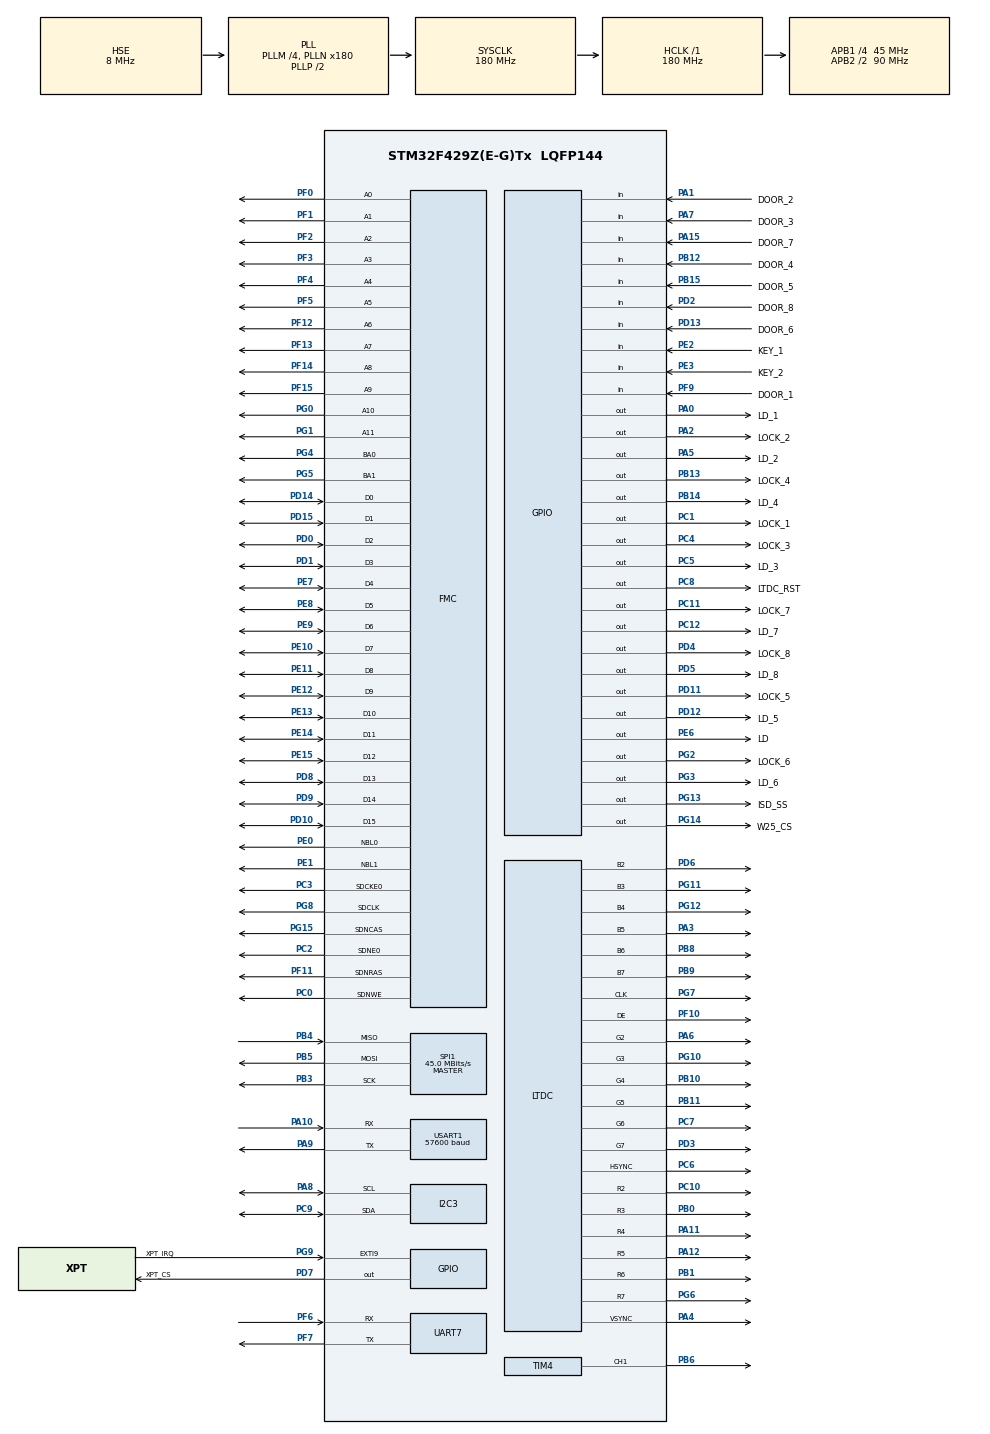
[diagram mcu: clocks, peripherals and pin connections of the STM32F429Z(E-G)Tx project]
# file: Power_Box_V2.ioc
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Dma.Request0=UART7_RX
Dma.UART7_RX.0.Direction=DMA_PERIPH_TO_MEMORY
Dma.UART7_RX.0.FIFOMode=DMA_FIFOMODE_DISABLE
Dma.UART7_RX.0.Instance=DMA1_Stream3
Dma.UART7_RX.0.MemDataAlignment=DMA_MDATAALIGN_BYTE
Dma.UART7_RX.0.MemInc=DMA_MINC_ENABLE
Dma.UART7_RX.0.Mode=DMA_CIRCULAR
Dma.UART7_RX.0.PeriphDataAlignment=DMA_PDATAALIGN_BYTE
Dma.UART7_RX.0.PeriphInc=DMA_PINC_DISABLE
Dma.UART7_RX.0.Priority=DMA_PRIORITY_LOW
FMC.SDBank1=FMC_SDRAM_BANK1
Mcu.Family=STM32F4
Mcu.Name=STM32F429Z(E-G)Tx
Mcu.Package=LQFP144
NVIC.DMA1_Stream3_IRQn=true\:0\:0\:false\:false\:true\:false\:true\:true
NVIC.PriorityGroup=NVIC_PRIORITYGROUP_4
NVIC.TIM8_TRG_COM_TIM14_IRQn=true\:0\:0\:false\:false\:true\:true\:true\:true
NVIC.UART7_IRQn=true\:0\:0\:false\:false\:true\:true\:true\:true
PA0/WKUP.GPIO_Label=LD_1
PA0/WKUP.Signal=GPIO_Output
PA1.GPIO_Label=DOOR_2
PA1.Signal=GPIO_Input
PA10.Mode=Asynchronous
PA10.Signal=USART1_RX
PA11.Mode=RGB666
PA11.Signal=LTDC_R4
PA12.Mode=RGB666
PA12.Signal=LTDC_R5
PA13.Mode=Serial_Wire
PA13.Signal=SYS_JTMS-SWDIO
PA14.Mode=Serial_Wire
PA14.Signal=SYS_JTCK-SWCLK
PA15.GPIO_Label=DOOR_7
PA15.Signal=GPIO_Input
PA2.GPIO_Label=LOCK_2
PA2.Signal=GPIO_Output
PA3.Mode=RGB666
PA3.Signal=LTDC_B5
PA4.Mode=RGB666
PA4.Signal=LTDC_VSYNC
PA5.GPIO_Label=LD_2
PA5.Signal=GPIO_Output
PA6.Mode=RGB666
PA6.Signal=LTDC_G2
PA7.GPIO_Label=DOOR_3
PA7.Signal=GPIO_Input
PA8.Mode=I2C
PA8.Signal=I2C3_SCL
PA9.Mode=Asynchronous
PA9.Signal=USART1_TX
PB0.Mode=RGB666
PB0.Signal=LTDC_R3
PB1.Mode=RGB666
PB1.Signal=LTDC_R6
PB10.Mode=RGB666
PB10.Signal=LTDC_G4
PB11.Mode=RGB666
PB11.Signal=LTDC_G5
PB12.GPIO_Label=DOOR_4
PB12.Signal=GPIO_Input
PB13.GPIO_Label=LOCK_4
PB13.Signal=GPIO_Output
PB14.GPIO_Label=LD_4
PB14.Signal=GPIO_Output
PB15.GPIO_Label=DOOR_5
PB15.Signal=GPIO_Input
PB3.Mode=Full_Duplex_Master
PB3.Signal=SPI1_SCK
PB4.Mode=Full_Duplex_Master
PB4.Signal=SPI1_MISO
PB5.Mode=Full_Duplex_Master
PB5.Signal=SPI1_MOSI
PB6.Signal=S_TIM4_CH1
PB8.Mode=RGB666
PB8.Signal=LTDC_B6
PB9.Mode=RGB666
PB9.Signal=LTDC_B7
PC0.Signal=FMC_SDNWE
PC1.GPIO_Label=LOCK_1
PC1.Signal=GPIO_Output
PC10.Mode=RGB666
PC10.Signal=LTDC_R2
PC11.GPIO_Label=LOCK_7
PC11.Signal=GPIO_Output
PC12.GPIO_Label=LD_7
PC12.Signal=GPIO_Output
PC14/OSC32_IN.Mode=LSE-External-Oscillator
PC14/OSC32_IN.Signal=RCC_OSC32_IN
PC15/OSC32_OUT.Mode=LSE-External-Oscillator
PC15/OSC32_OUT.Signal=RCC_OSC32_OUT
PC2.Mode=SdramChipSelect1_1
PC2.Signal=FMC_SDNE0
PC3.Mode=SdramChipSelect1_1
PC3.Signal=FMC_SDCKE0
PC4.GPIO_Label=LOCK_3
PC4.Signal=GPIO_Output
PC5.GPIO_Label=LD_3
PC5.Signal=GPIO_Output
PC6.Mode=RGB666
PC6.Signal=LTDC_HSYNC
PC7.Mode=RGB666
PC7.Signal=LTDC_G6
PC8.GPIO_Label=LTDC_RST
PC8.Signal=GPIO_Output
PC9.Mode=I2C
PC9.Signal=I2C3_SDA
PD0.Signal=FMC_D2_DA2
PD1.Signal=FMC_D3_DA3
PD10.Signal=FMC_D15_DA15
PD11.GPIO_Label=LOCK_5
PD11.Signal=GPIO_Output
PD12.GPIO_Label=LD_5
PD12.Signal=GPIO_Output
PD13.GPIO_Label=DOOR_6
PD13.Signal=GPIO_Input
PD14.Signal=FMC_D0_DA0
PD15.Signal=FMC_D1_DA1
PD2.GPIO_Label=DOOR_8
PD2.Signal=GPIO_Input
PD3.Mode=RGB666
PD3.Signal=LTDC_G7
PD4.GPIO_Label=LOCK_8
PD4.Signal=GPIO_Output
PD5.GPIO_Label=LD_8
PD5.Signal=GPIO_Output
PD6.Mode=RGB666
PD6.Signal=LTDC_B2
PD7.GPIO_Label=XPT_CS
PD7.Signal=GPIO_Output
PD8.Signal=FMC_D13_DA13
PD9.Signal=FMC_D14_DA14
PE0.Signal=FMC_NBL0
PE1.Signal=FMC_NBL1
PE10.Signal=FMC_D7_DA7
PE11.Signal=FMC_D8_DA8
PE12.Signal=FMC_D9_DA9
PE13.Signal=FMC_D10_DA10
PE14.Signal=FMC_D11_DA11
PE15.Signal=FMC_D12_DA12
PE2.GPIO_Label=KEY_1
PE2.Signal=GPIO_Input
PE3.GPIO_Label=KEY_2
PE3.Signal=GPIO_Input
PE6.GPIO_Label=LD
PE6.Signal=GPIO_Output
PE7.Signal=FMC_D4_DA4
PE8.Signal=FMC_D5_DA5
PE9.Signal=FMC_D6_DA6
PF0.Signal=FMC_A0
PF1.Signal=FMC_A1
PF10.Mode=RGB666
PF10.Signal=LTDC_DE
PF11.Signal=FMC_SDNRAS
PF12.Signal=FMC_A6
PF13.Signal=FMC_A7
PF14.Signal=FMC_A8
PF15.Signal=FMC_A9
PF2.Signal=FMC_A2
PF3.Signal=FMC_A3
PF4.Signal=FMC_A4
PF5.Signal=FMC_A5
PF6.Mode=Asynchronous
PF6.Signal=UART7_RX
PF7.Mode=Asynchronous
PF7.Signal=UART7_TX
PF9.GPIO_Label=DOOR_1
PF9.Signal=GPIO_Input
PG0.Signal=FMC_A10
PG1.Signal=FMC_A11
PG10.Mode=RGB666
PG10.Signal=LTDC_G3
PG11.Mode=RGB666
PG11.Signal=LTDC_B3
PG12.Mode=RGB666
PG12.Signal=LTDC_B4
PG13.GPIO_Label=ISD_SS
PG13.Signal=GPIO_Output
PG14.GPIO_Label=W25_CS
PG14.Signal=GPIO_Output
PG15.Signal=FMC_SDNCAS
PG2.GPIO_Label=LOCK_6
PG2.Signal=GPIO_Output
PG3.GPIO_Label=LD_6
PG3.Signal=GPIO_Output
PG4.Signal=FMC_A14_BA0
PG5.Signal=FMC_A15_BA1
PG6.Mode=RGB666
PG6.Signal=LTDC_R7
PG7.Mode=RGB666
PG7.Signal=LTDC_CLK
PG8.Signal=FMC_SDCLK
PG9.GPIO_Label=XPT_IRQ
PG9.Signal=GPXTI9
PH0/OSC_IN.Mode=HSE-External-Oscillator
PH0/OSC_IN.Signal=RCC_OSC_IN
PH1/OSC_OUT.Mode=HSE-External-Oscillator
PH1/OSC_OUT.Signal=RCC_OSC_OUT
ProjectManager.HeapSize=0x2000
ProjectManager.StackSize=0x2000
ProjectManager.TargetToolchain=MDK-ARM V5
RCC.48MHZClocksFreq_Value=90000000
RCC.AHBFreq_Value=180000000
RCC.APB1CLKDivider=RCC_HCLK_DIV4
RCC.APB1Freq_Value=45000000
RCC.APB1TimFreq_Value=90000000
RCC.APB2CLKDivider=RCC_HCLK_DIV2
RCC.APB2Freq_Value=90000000
RCC.APB2TimFreq_Value=180000000
RCC.CortexFreq_Value=180000000
RCC.EnbaleCSS=true
RCC.HCLKFreq_Value=180000000
RCC.HSE_VALUE=8000000
RCC.HSI_VALUE=16000000
RCC.PLLM=4
RCC.PLLN=180
RCC.PLLSAIN=50
RCC.PLLSourceVirtual=RCC_PLLSOURCE_HSE
RCC.RCC_RTC_Clock_Source=RCC_RTCCLKSOURCE_LSE
RCC.RCC_RTC_Clock_SourceVirtual=RCC_RTCCLKSOURCE_LSE
RCC.SYSCLKFreq_VALUE=180000000
RCC.SYSCLKSource=RCC_SYSCLKSOURCE_PLLCLK
RCC.VCOOutputFreq_Value=360000000
SH.FMC_A0.0=FMC_A0,12b-sda1
SH.FMC_A1.0=FMC_A1,12b-sda1
SH.FMC_A10.0=FMC_A10,12b-sda1
SH.FMC_A11.0=FMC_A11,12b-sda1
SH.FMC_A14_BA0.0=FMC_BA0,FourSdramBanks1
SH.FMC_A15_BA1.0=FMC_BA1,FourSdramBanks1
SH.FMC_A2.0=FMC_A2,12b-sda1
SH.FMC_A3.0=FMC_A3,12b-sda1
SH.FMC_A4.0=FMC_A4,12b-sda1
SH.FMC_A5.0=FMC_A5,12b-sda1
SH.FMC_A6.0=FMC_A6,12b-sda1
SH.FMC_A7.0=FMC_A7,12b-sda1
SH.FMC_A8.0=FMC_A8,12b-sda1
SH.FMC_A9.0=FMC_A9,12b-sda1
SH.FMC_D0_DA0.0=FMC_D0,sd-16b-d1
SH.FMC_D10_DA10.0=FMC_D10,sd-16b-d1
SH.FMC_D11_DA11.0=FMC_D11,sd-16b-d1
SH.FMC_D12_DA12.0=FMC_D12,sd-16b-d1
SH.FMC_D13_DA13.0=FMC_D13,sd-16b-d1
SH.FMC_D14_DA14.0=FMC_D14,sd-16b-d1
SH.FMC_D15_DA15.0=FMC_D15,sd-16b-d1
SH.FMC_D1_DA1.0=FMC_D1,sd-16b-d1
SH.FMC_D2_DA2.0=FMC_D2,sd-16b-d1
SH.FMC_D3_DA3.0=FMC_D3,sd-16b-d1
SH.FMC_D4_DA4.0=FMC_D4,sd-16b-d1
SH.FMC_D5_DA5.0=FMC_D5,sd-16b-d1
SH.FMC_D6_DA6.0=FMC_D6,sd-16b-d1
SH.FMC_D7_DA7.0=FMC_D7,sd-16b-d1
SH.FMC_D8_DA8.0=FMC_D8,sd-16b-d1
SH.FMC_D9_DA9.0=FMC_D9,sd-16b-d1
SH.FMC_NBL0.0=FMC_NBL0,Sd2ByteEnable1
SH.FMC_NBL1.0=FMC_NBL1,Sd2ByteEnable1
SH.FMC_SDCLK.0=FMC_SDCLK,12b-sda1
SH.FMC_SDNCAS.0=FMC_SDNCAS,12b-sda1
SH.FMC_SDNRAS.0=FMC_SDNRAS,12b-sda1
SH.FMC_SDNWE.0=FMC_SDNWE,12b-sda1
SH.S_TIM4_CH1.0=TIM4_CH1,PWM Generation1 CH1
SPI1.CalculateBaudRate=45.0 MBits/s
SPI1.Direction=SPI_DIRECTION_2LINES
SPI1.Mode=SPI_MODE_MASTER
SPI1.VirtualType=VM_MASTER
TIM14.AutoReloadPreload=TIM_AUTORELOAD_PRELOAD_ENABLE
TIM14.Period=999
TIM14.Prescaler=8999
TIM4.Channel-PWM\ Generation1\ CH1=TIM_CHANNEL_1
UART7.VirtualMode=Asynchronous
USART1.BaudRate=57600
USART1.VirtualMode=VM_ASYNC
VP_RTC_VS_RTC_Activate.Mode=RTC_Enabled
VP_RTC_VS_RTC_Calendar.Mode=RTC_Calendar
VP_TIM14_VS_ClockSourceINT.Mode=Enable_Timer
board=custom

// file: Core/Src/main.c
/* USER CODE BEGIN Header */
/**
  ******************************************************************************
  * @file           : main.c
  * @brief          : Main program body
  ******************************************************************************
  * @attention
  *
  * Copyright (c) 2026 STMicroelectronics.
  * All rights reserved.
  *
  * This software is licensed under terms that can be found in the LICENSE file
  * in the root directory of this software component.
  * If no LICENSE file comes with this software, it is provided AS-IS.
  *
  ******************************************************************************
  */
/* USER CODE END Header */
#include "main.h"

/* USER CODE BEGIN Includes */
#include "w25q32.h"
#include "spi_bus.h"
#include "lcd.h"
#include "backlight.h"
#include "sdram.h"
#include "touch.h"
#include "isd1730.h"
#include "zfm40.h"
#include "AT24Cxx.h"
#include "rtc.h"
#include "debug_link.h"
#include "ui_interface.h"
#include "channel_hw.h"
#include "channel_manager.h"
#include "storage.h"
#include "log.h"
#include "flow_manager.h"
/* USER CODE END Includes */

/* USER CODE BEGIN PD */
/* PA0 blinks once when a scanned finger matches a template already
   stored in the module; not currently driven by application code, but
   left configured (safe, off) as an available feedback hook. */
#define FP_MATCH_LED_GPIO_Port     GPIOA
#define FP_MATCH_LED_Pin           GPIO_PIN_0
/* USER CODE END PD */

I2C_HandleTypeDef hi2c3;

LTDC_HandleTypeDef hltdc;

RTC_HandleTypeDef hrtc;

SPI_HandleTypeDef hspi1;

TIM_HandleTypeDef htim4;
TIM_HandleTypeDef htim14;

UART_HandleTypeDef huart7;
UART_HandleTypeDef huart1;
DMA_HandleTypeDef hdma_uart7_rx;

SDRAM_HandleTypeDef hsdram1;

void SystemClock_Config(void);
static void MX_GPIO_Init(void);
static void MX_DMA_Init(void);
static void MX_LTDC_Init(void);
static void MX_FMC_Init(void);
static void MX_I2C3_Init(void);
static void MX_SPI1_Init(void);
static void MX_USART1_UART_Init(void);
static void MX_TIM4_Init(void);
static void MX_RTC_Init(void);
static void MX_TIM14_Init(void);
static void MX_UART7_Init(void);

int main(void)
{

  /* MCU Configuration--------------------------------------------------------*/

  /* Reset of all peripherals, Initializes the Flash interface and the Systick. */
  HAL_Init();

  /* Configure the system clock */
  SystemClock_Config();

  /* Initialize all configured peripherals */
  MX_GPIO_Init();
  MX_DMA_Init();
  MX_LTDC_Init();
  MX_FMC_Init();
  MX_I2C3_Init();
  MX_SPI1_Init();
  MX_USART1_UART_Init();
  MX_TIM4_Init();
  MX_RTC_Init();
  MX_TIM14_Init();
  MX_UART7_Init();
  /* USER CODE BEGIN 2 */

  HAL_TIM_Base_Start_IT(&htim14);

  /* DebugLink first: no peripheral dependency beyond MX_UART7_Init()
   * (already done above), and every later init-failure message below
   * needs it ready to actually reach the PC tool. */
  DebugLink_Init(&huart7);
  DebugLink_RegisterCallback(UI_ProcessIncomingLine);
  UI_Init();

  /* ---- Boot sequence: order matters, see each module's header for its
   * documented dependency on the ones before it. ---- */
  Backlight_Init();
  Backlight_SetBrightness(50);

  RTC_Init();

  SPI_Bus_Init();                 /* must precede ISD1730_Init() / W25Q32_Init() */
  if (ISD1730_Init() != ISD_OK)
  {
      DebugLink_SendLine("OUT:LOG:ISD1730_Init failed");
  }
  if (W25Q32_Init() != W25_OK)
  {
      DebugLink_SendLine("OUT:LOG:W25Q32_Init failed");
  }

  if (ZFM40_Init() != ZFM_OK)
  {
      DebugLink_SendLine("OUT:LOG:ZFM40_Init failed");
  }
  HAL_Delay(500); /* module boot time before the first command */
  {
      uint8_t confirm;
      if ((ZFM40_VerifyPassword(0x00000000, &confirm) != ZFM_OK) || (confirm != ZFM_CONF_OK))
      {
          DebugLink_SendLine("OUT:LOG:ZFM40 password verify failed");
      }
  }

  if (ChannelHW_Init() != SYS_OK)     /* before Storage_Init()/ChannelManager_Init() */
  {
      DebugLink_SendLine("OUT:LOG:ChannelHW_Init failed");
  }
  if (Storage_Init() != SYS_OK)       /* before Log_Init()/ChannelManager_Init() */
  {
      DebugLink_SendLine("OUT:LOG:Storage_Init failed");
  }
  if (Log_Init() != SYS_OK)           /* needs Storage_Init() + W25Q32_Init() */
  {
      DebugLink_SendLine("OUT:LOG:Log_Init failed");
  }
  if (ChannelManager_Init() != SYS_OK) /* needs Storage_Init() + ChannelHW_Init() */
  {
      DebugLink_SendLine("OUT:LOG:ChannelManager_Init failed");
  }

  FlowManager_Init();
  /* USER CODE END 2 */

  /* Infinite loop */
  while (1)
  {

    /* USER CODE BEGIN 3 */
    DebugLink_Process();
    UI_Tick();
    FlowManager_Process();
  }
  /* USER CODE END 3 */
}

void SystemClock_Config(void)
{
  RCC_OscInitTypeDef RCC_OscInitStruct = {0};
  RCC_ClkInitTypeDef RCC_ClkInitStruct = {0};

  /** Configure the main internal regulator output voltage
  */
  __HAL_RCC_PWR_CLK_ENABLE();
  __HAL_PWR_VOLTAGESCALING_CONFIG(PWR_REGULATOR_VOLTAGE_SCALE1);

  /** Initializes the RCC Oscillators according to the specified parameters
  * in the RCC_OscInitTypeDef structure.
  */
  RCC_OscInitStruct.OscillatorType = RCC_OSCILLATORTYPE_HSE|RCC_OSCILLATORTYPE_LSE;
  RCC_OscInitStruct.HSEState = RCC_HSE_ON;
  RCC_OscInitStruct.LSEState = RCC_LSE_ON;
  RCC_OscInitStruct.PLL.PLLState = RCC_PLL_ON;
  RCC_OscInitStruct.PLL.PLLSource = RCC_PLLSOURCE_HSE;
  RCC_OscInitStruct.PLL.PLLM = 4;
  RCC_OscInitStruct.PLL.PLLN = 180;
  RCC_OscInitStruct.PLL.PLLP = RCC_PLLP_DIV2;
  RCC_OscInitStruct.PLL.PLLQ = 4;
  if (HAL_RCC_OscConfig(&RCC_OscInitStruct) != HAL_OK)
  {
    Error_Handler();
  }

  /** Activate the Over-Drive mode
  */
  if (HAL_PWREx_EnableOverDrive() != HAL_OK)
  {
    Error_Handler();
  }

  /** Initializes the CPU, AHB and APB buses clocks
  */
  RCC_ClkInitStruct.ClockType = RCC_CLOCKTYPE_HCLK|RCC_CLOCKTYPE_SYSCLK
                              |RCC_CLOCKTYPE_PCLK1|RCC_CLOCKTYPE_PCLK2;
  RCC_ClkInitStruct.SYSCLKSource = RCC_SYSCLKSOURCE_PLLCLK;
  RCC_ClkInitStruct.AHBCLKDivider = RCC_SYSCLK_DIV1;
  RCC_ClkInitStruct.APB1CLKDivider = RCC_HCLK_DIV4;
  RCC_ClkInitStruct.APB2CLKDivider = RCC_HCLK_DIV2;

  if (HAL_RCC_ClockConfig(&RCC_ClkInitStruct, FLASH_LATENCY_5) != HAL_OK)
  {
    Error_Handler();
  }

  /** Enables the Clock Security System
  */
  HAL_RCC_EnableCSS();
}

static void MX_I2C3_Init(void)
{

  hi2c3.Instance = I2C3;
  hi2c3.Init.ClockSpeed = 100000;
  hi2c3.Init.DutyCycle = I2C_DUTYCYCLE_2;
  hi2c3.Init.OwnAddress1 = 0;
  hi2c3.Init.AddressingMode = I2C_ADDRESSINGMODE_7BIT;
  hi2c3.Init.DualAddressMode = I2C_DUALADDRESS_DISABLE;
  hi2c3.Init.OwnAddress2 = 0;
  hi2c3.Init.GeneralCallMode = I2C_GENERALCALL_DISABLE;
  hi2c3.Init.NoStretchMode = I2C_NOSTRETCH_DISABLE;
  if (HAL_I2C_Init(&hi2c3) != HAL_OK)
  {
    Error_Handler();
  }

  /** Configure Analogue filter
  */
  if (HAL_I2CEx_ConfigAnalogFilter(&hi2c3, I2C_ANALOGFILTER_ENABLE) != HAL_OK)
  {
    Error_Handler();
  }

  /** Configure Digital filter
  */
  if (HAL_I2CEx_ConfigDigitalFilter(&hi2c3, 0) != HAL_OK)
  {
    Error_Handler();
  }

}

static void MX_LTDC_Init(void)
{

  LTDC_LayerCfgTypeDef pLayerCfg = {0};
  LTDC_LayerCfgTypeDef pLayerCfg1 = {0};

  hltdc.Instance = LTDC;
  hltdc.Init.HSPolarity = LTDC_HSPOLARITY_AL;
  hltdc.Init.VSPolarity = LTDC_VSPOLARITY_AL;
  hltdc.Init.DEPolarity = LTDC_DEPOLARITY_AL;
  hltdc.Init.PCPolarity = LTDC_PCPOLARITY_IPC;
  hltdc.Init.HorizontalSync = 7;
  hltdc.Init.VerticalSync = 3;
  hltdc.Init.AccumulatedHBP = 14;
  hltdc.Init.AccumulatedVBP = 5;
  hltdc.Init.AccumulatedActiveW = 654;
  hltdc.Init.AccumulatedActiveH = 485;
  hltdc.Init.TotalWidth = 660;
  hltdc.Init.TotalHeigh = 487;
  hltdc.Init.Backcolor.Blue = 0;
  hltdc.Init.Backcolor.Green = 0;
  hltdc.Init.Backcolor.Red = 0;
  if (HAL_LTDC_Init(&hltdc) != HAL_OK)
  {
    Error_Handler();
  }
  pLayerCfg.WindowX0 = 0;
  pLayerCfg.WindowX1 = 0;
  pLayerCfg.WindowY0 = 0;
  pLayerCfg.WindowY1 = 0;
  pLayerCfg.PixelFormat = LTDC_PIXEL_FORMAT_ARGB8888;
  pLayerCfg.Alpha = 0;
  pLayerCfg.Alpha0 = 0;
  pLayerCfg.BlendingFactor1 = LTDC_BLENDING_FACTOR1_CA;
  pLayerCfg.BlendingFactor2 = LTDC_BLENDING_FACTOR2_CA;
  pLayerCfg.FBStartAdress = 0;
  pLayerCfg.ImageWidth = 0;
  pLayerCfg.ImageHeight = 0;
  pLayerCfg.Backcolor.Blue = 0;
  pLayerCfg.Backcolor.Green = 0;
  pLayerCfg.Backcolor.Red = 0;
  if (HAL_LTDC_ConfigLayer(&hltdc, &pLayerCfg, 0) != HAL_OK)
  {
    Error_Handler();
  }
  pLayerCfg1.WindowX0 = 0;
  pLayerCfg1.WindowX1 = 0;
  pLayerCfg1.WindowY0 = 0;
  pLayerCfg1.WindowY1 = 0;
  pLayerCfg1.PixelFormat = LTDC_PIXEL_FORMAT_ARGB8888;
  pLayerCfg1.Alpha = 0;
  pLayerCfg1.Alpha0 = 0;
  pLayerCfg1.BlendingFactor1 = LTDC_BLENDING_FACTOR1_CA;
  pLayerCfg1.BlendingFactor2 = LTDC_BLENDING_FACTOR2_CA;
  pLayerCfg1.FBStartAdress = 0;
  pLayerCfg1.ImageWidth = 0;
  pLayerCfg1.ImageHeight = 0;
  pLayerCfg1.Backcolor.Blue = 0;
  pLayerCfg1.Backcolor.Green = 0;
  pLayerCfg1.Backcolor.Red = 0;
  if (HAL_LTDC_ConfigLayer(&hltdc, &pLayerCfg1, 1) != HAL_OK)
  {
    Error_Handler();
  }

}

static void MX_RTC_Init(void)
{

  RTC_TimeTypeDef sTime = {0};
  RTC_DateTypeDef sDate = {0};

  /** Initialize RTC Only
  */
  hrtc.Instance = RTC;
  hrtc.Init.HourFormat = RTC_HOURFORMAT_24;
  hrtc.Init.AsynchPrediv = 127;
  hrtc.Init.SynchPrediv = 255;
  hrtc.Init.OutPut = RTC_OUTPUT_DISABLE;
  hrtc.Init.OutPutPolarity = RTC_OUTPUT_POLARITY_HIGH;
  hrtc.Init.OutPutType = RTC_OUTPUT_TYPE_OPENDRAIN;
  if (HAL_RTC_Init(&hrtc) != HAL_OK)
  {
    Error_Handler();
  }

  /* USER CODE BEGIN Check_RTC_BKUP */
  if (HAL_RTCEx_BKUPRead(&hrtc, RTC_BKP_DR0) == RTC_COLD_START_MAGIC)
  {
    /* VBAT has kept a real calendar running since a previous boot --
     * skip CubeMX's unconditional default below, don't stomp it. */
    return;
  }
  /* USER CODE END Check_RTC_BKUP */

  /** Initialize RTC and set the Time and Date
  */
  sTime.Hours = 0x0;
  sTime.Minutes = 0x0;
  sTime.Seconds = 0x0;
  sTime.DayLightSaving = RTC_DAYLIGHTSAVING_NONE;
  sTime.StoreOperation = RTC_STOREOPERATION_RESET;
  if (HAL_RTC_SetTime(&hrtc, &sTime, RTC_FORMAT_BCD) != HAL_OK)
  {
    Error_Handler();
  }
  sDate.WeekDay = RTC_WEEKDAY_MONDAY;
  sDate.Month = RTC_MONTH_JANUARY;
  sDate.Date = 0x1;
  sDate.Year = 0x0;

  if (HAL_RTC_SetDate(&hrtc, &sDate, RTC_FORMAT_BCD) != HAL_OK)
  {
    Error_Handler();
  }

}

static void MX_SPI1_Init(void)
{

  /* SPI1 parameter configuration*/
  hspi1.Instance = SPI1;
  hspi1.Init.Mode = SPI_MODE_MASTER;
  hspi1.Init.Direction = SPI_DIRECTION_2LINES;
  hspi1.Init.DataSize = SPI_DATASIZE_8BIT;
  hspi1.Init.CLKPolarity = SPI_POLARITY_LOW;
  hspi1.Init.CLKPhase = SPI_PHASE_1EDGE;
  hspi1.Init.NSS = SPI_NSS_SOFT;
  hspi1.Init.BaudRatePrescaler = SPI_BAUDRATEPRESCALER_2;
  hspi1.Init.FirstBit = SPI_FIRSTBIT_MSB;
  hspi1.Init.TIMode = SPI_TIMODE_DISABLE;
  hspi1.Init.CRCCalculation = SPI_CRCCALCULATION_DISABLE;
  hspi1.Init.CRCPolynomial = 10;
  if (HAL_SPI_Init(&hspi1) != HAL_OK)
  {
    Error_Handler();
  }

}

static void MX_TIM4_Init(void)
{

  TIM_MasterConfigTypeDef sMasterConfig = {0};
  TIM_OC_InitTypeDef sConfigOC = {0};

  htim4.Instance = TIM4;
  htim4.Init.Prescaler = 0;
  htim4.Init.CounterMode = TIM_COUNTERMODE_UP;
  htim4.Init.Period = 65535;
  htim4.Init.ClockDivision = TIM_CLOCKDIVISION_DIV1;
  htim4.Init.AutoReloadPreload = TIM_AUTORELOAD_PRELOAD_DISABLE;
  if (HAL_TIM_PWM_Init(&htim4) != HAL_OK)
  {
    Error_Handler();
  }
  sMasterConfig.MasterOutputTrigger = TIM_TRGO_RESET;
  sMasterConfig.MasterSlaveMode = TIM_MASTERSLAVEMODE_DISABLE;
  if (HAL_TIMEx_MasterConfigSynchronization(&htim4, &sMasterConfig) != HAL_OK)
  {
    Error_Handler();
  }
  sConfigOC.OCMode = TIM_OCMODE_PWM1;
  sConfigOC.Pulse = 0;
  sConfigOC.OCPolarity = TIM_OCPOLARITY_HIGH;
  sConfigOC.OCFastMode = TIM_OCFAST_DISABLE;
  if (HAL_TIM_PWM_ConfigChannel(&htim4, &sConfigOC, TIM_CHANNEL_1) != HAL_OK)
  {
    Error_Handler();
  }
  HAL_TIM_MspPostInit(&htim4);

}

static void MX_TIM14_Init(void)
{

  htim14.Instance = TIM14;
  htim14.Init.Prescaler = 8999;
  htim14.Init.CounterMode = TIM_COUNTERMODE_UP;
  htim14.Init.Period = 999;
  htim14.Init.ClockDivision = TIM_CLOCKDIVISION_DIV1;
  htim14.Init.AutoReloadPreload = TIM_AUTORELOAD_PRELOAD_ENABLE;
  if (HAL_TIM_Base_Init(&htim14) != HAL_OK)
  {
    Error_Handler();
  }

}

static void MX_UART7_Init(void)
{

  huart7.Instance = UART7;
  huart7.Init.BaudRate = 115200;
  huart7.Init.WordLength = UART_WORDLENGTH_8B;
  huart7.Init.StopBits = UART_STOPBITS_1;
  huart7.Init.Parity = UART_PARITY_NONE;
  huart7.Init.Mode = UART_MODE_TX_RX;
  huart7.Init.HwFlowCtl = UART_HWCONTROL_NONE;
  huart7.Init.OverSampling = UART_OVERSAMPLING_16;
  if (HAL_UART_Init(&huart7) != HAL_OK)
  {
    Error_Handler();
  }

}

static void MX_USART1_UART_Init(void)
{

  huart1.Instance = USART1;
  huart1.Init.BaudRate = 57600;
  huart1.Init.WordLength = UART_WORDLENGTH_8B;
  huart1.Init.StopBits = UART_STOPBITS_1;
  huart1.Init.Parity = UART_PARITY_NONE;
  huart1.Init.Mode = UART_MODE_TX_RX;
  huart1.Init.HwFlowCtl = UART_HWCONTROL_NONE;
  huart1.Init.OverSampling = UART_OVERSAMPLING_16;
  if (HAL_UART_Init(&huart1) != HAL_OK)
  {
    Error_Handler();
  }

}

static void MX_DMA_Init(void)
{

  /* DMA controller clock enable */
  __HAL_RCC_DMA1_CLK_ENABLE();

  /* DMA interrupt init */
  /* DMA1_Stream3_IRQn interrupt configuration */
  HAL_NVIC_SetPriority(DMA1_Stream3_IRQn, 0, 0);
  HAL_NVIC_EnableIRQ(DMA1_Stream3_IRQn);

}

/* FMC initialization function */
static void MX_FMC_Init(void)
{

  FMC_SDRAM_TimingTypeDef SdramTiming = {0};

  /** Perform the SDRAM1 memory initialization sequence
  */
  hsdram1.Instance = FMC_SDRAM_DEVICE;
  /* hsdram1.Init */
  hsdram1.Init.SDBank = FMC_SDRAM_BANK1;
  hsdram1.Init.ColumnBitsNumber = FMC_SDRAM_COLUMN_BITS_NUM_8;
  hsdram1.Init.RowBitsNumber = FMC_SDRAM_ROW_BITS_NUM_12;
  hsdram1.Init.MemoryDataWidth = FMC_SDRAM_MEM_BUS_WIDTH_16;
  hsdram1.Init.InternalBankNumber = FMC_SDRAM_INTERN_BANKS_NUM_4;
  hsdram1.Init.CASLatency = FMC_SDRAM_CAS_LATENCY_1;
  hsdram1.Init.WriteProtection = FMC_SDRAM_WRITE_PROTECTION_DISABLE;
  hsdram1.Init.SDClockPeriod = FMC_SDRAM_CLOCK_DISABLE;
  hsdram1.Init.ReadBurst = FMC_SDRAM_RBURST_DISABLE;
  hsdram1.Init.ReadPipeDelay = FMC_SDRAM_RPIPE_DELAY_0;
  /* SdramTiming */
  SdramTiming.LoadToActiveDelay = 16;
  SdramTiming.ExitSelfRefreshDelay = 16;
  SdramTiming.SelfRefreshTime = 16;
  SdramTiming.RowCycleDelay = 16;
  SdramTiming.WriteRecoveryTime = 16;
  SdramTiming.RPDelay = 16;
  SdramTiming.RCDDelay = 16;

  if (HAL_SDRAM_Init(&hsdram1, &SdramTiming) != HAL_OK)
  {
    Error_Handler( );
  }

}

static void MX_GPIO_Init(void)
{
  GPIO_InitTypeDef GPIO_InitStruct = {0};

  /* GPIO Ports Clock Enable */
  __HAL_RCC_GPIOE_CLK_ENABLE();
  __HAL_RCC_GPIOC_CLK_ENABLE();
  __HAL_RCC_GPIOF_CLK_ENABLE();
  __HAL_RCC_GPIOH_CLK_ENABLE();
  __HAL_RCC_GPIOA_CLK_ENABLE();
  __HAL_RCC_GPIOB_CLK_ENABLE();
  __HAL_RCC_GPIOG_CLK_ENABLE();
  __HAL_RCC_GPIOD_CLK_ENABLE();

  /*Configure GPIO pin Output Level */
  HAL_GPIO_WritePin(LD_GPIO_Port, LD_Pin, GPIO_PIN_RESET);

  /*Configure GPIO pin Output Level */
  HAL_GPIO_WritePin(GPIOC, LOCK_1_Pin|LOCK_3_Pin|LD_3_Pin|LTDC_RST_Pin
                          |LOCK_7_Pin|LD_7_Pin, GPIO_PIN_RESET);

  /*Configure GPIO pin Output Level */
  HAL_GPIO_WritePin(GPIOA, LD_1_Pin|LOCK_2_Pin|LD_2_Pin, GPIO_PIN_RESET);

  /*Configure GPIO pin Output Level */
  HAL_GPIO_WritePin(GPIOB, LOCK_4_Pin|LD_4_Pin, GPIO_PIN_RESET);

  /*Configure GPIO pin Output Level */
  HAL_GPIO_WritePin(GPIOD, LOCK_5_Pin|LD_5_Pin|LOCK_8_Pin|LD_8_Pin
                          |XPT_CS_Pin, GPIO_PIN_RESET);

  /*Configure GPIO pin Output Level */
  HAL_GPIO_WritePin(GPIOG, LOCK_6_Pin|LD_6_Pin|ISD_SS_Pin|W25_CS_Pin, GPIO_PIN_RESET);

  /*Configure GPIO pins : KEY_1_Pin KEY_2_Pin */
  GPIO_InitStruct.Pin = KEY_1_Pin|KEY_2_Pin;
  GPIO_InitStruct.Mode = GPIO_MODE_INPUT;
  GPIO_InitStruct.Pull = GPIO_NOPULL;
  HAL_GPIO_Init(GPIOE, &GPIO_InitStruct);

  /*Configure GPIO pin : LD_Pin */
  GPIO_InitStruct.Pin = LD_Pin;
  GPIO_InitStruct.Mode = GPIO_MODE_OUTPUT_PP;
  GPIO_InitStruct.Pull = GPIO_NOPULL;
  GPIO_InitStruct.Speed = GPIO_SPEED_FREQ_LOW;
  HAL_GPIO_Init(LD_GPIO_Port, &GPIO_InitStruct);

  /*Configure GPIO pin : DOOR_1_Pin */
  GPIO_InitStruct.Pin = DOOR_1_Pin;
  GPIO_InitStruct.Mode = GPIO_MODE_INPUT;
  GPIO_InitStruct.Pull = GPIO_NOPULL;
  HAL_GPIO_Init(DOOR_1_GPIO_Port, &GPIO_InitStruct);

  /*Configure GPIO pins : LOCK_1_Pin LOCK_3_Pin LD_3_Pin LTDC_RST_Pin
                           LOCK_7_Pin LD_7_Pin */
  GPIO_InitStruct.Pin = LOCK_1_Pin|LOCK_3_Pin|LD_3_Pin|LTDC_RST_Pin
                          |LOCK_7_Pin|LD_7_Pin;
  GPIO_InitStruct.Mode = GPIO_MODE_OUTPUT_PP;
  GPIO_InitStruct.Pull = GPIO_NOPULL;
  GPIO_InitStruct.Speed = GPIO_SPEED_FREQ_LOW;
  HAL_GPIO_Init(GPIOC, &GPIO_InitStruct);

  /*Configure GPIO pins : LD_1_Pin LOCK_2_Pin LD_2_Pin */
  GPIO_InitStruct.Pin = LD_1_Pin|LOCK_2_Pin|LD_2_Pin;
  GPIO_InitStruct.Mode = GPIO_MODE_OUTPUT_PP;
  GPIO_InitStruct.Pull = GPIO_NOPULL;
  GPIO_InitStruct.Speed = GPIO_SPEED_FREQ_LOW;
  HAL_GPIO_Init(GPIOA, &GPIO_InitStruct);

  /*Configure GPIO pins : DOOR_2_Pin DOOR_3_Pin DOOR_7_Pin */
  GPIO_InitStruct.Pin = DOOR_2_Pin|DOOR_3_Pin|DOOR_7_Pin;
  GPIO_InitStruct.Mode = GPIO_MODE_INPUT;
  GPIO_InitStruct.Pull = GPIO_NOPULL;
  HAL_GPIO_Init(GPIOA, &GPIO_InitStruct);

  /*Configure GPIO pins : DOOR_4_Pin DOOR_5_Pin */
  GPIO_InitStruct.Pin = DOOR_4_Pin|DOOR_5_Pin;
  GPIO_InitStruct.Mode = GPIO_MODE_INPUT;
  GPIO_InitStruct.Pull = GPIO_NOPULL;
  HAL_GPIO_Init(GPIOB, &GPIO_InitStruct);

  /*Configure GPIO pins : LOCK_4_Pin LD_4_Pin */
  GPIO_InitStruct.Pin = LOCK_4_Pin|LD_4_Pin;
  GPIO_InitStruct.Mode = GPIO_MODE_OUTPUT_PP;
  GPIO_InitStruct.Pull = GPIO_NOPULL;
  GPIO_InitStruct.Speed = GPIO_SPEED_FREQ_LOW;
  HAL_GPIO_Init(GPIOB, &GPIO_InitStruct);

  /*Configure GPIO pins : LOCK_5_Pin LD_5_Pin LOCK_8_Pin LD_8_Pin
                           XPT_CS_Pin */
  GPIO_InitStruct.Pin = LOCK_5_Pin|LD_5_Pin|LOCK_8_Pin|LD_8_Pin
                          |XPT_CS_Pin;
  GPIO_InitStruct.Mode = GPIO_MODE_OUTPUT_PP;
  GPIO_InitStruct.Pull = GPIO_NOPULL;
  GPIO_InitStruct.Speed = GPIO_SPEED_FREQ_LOW;
  HAL_GPIO_Init(GPIOD, &GPIO_InitStruct);

  /*Configure GPIO pins : DOOR_6_Pin DOOR_8_Pin */
  GPIO_InitStruct.Pin = DOOR_6_Pin|DOOR_8_Pin;
  GPIO_InitStruct.Mode = GPIO_MODE_INPUT;
  GPIO_InitStruct.Pull = GPIO_NOPULL;
  HAL_GPIO_Init(GPIOD, &GPIO_InitStruct);

  /*Configure GPIO pins : LOCK_6_Pin LD_6_Pin ISD_SS_Pin W25_CS_Pin */
  GPIO_InitStruct.Pin = LOCK_6_Pin|LD_6_Pin|ISD_SS_Pin|W25_CS_Pin;
  GPIO_InitStruct.Mode = GPIO_MODE_OUTPUT_PP;
  GPIO_InitStruct.Pull = GPIO_NOPULL;
  GPIO_InitStruct.Speed = GPIO_SPEED_FREQ_LOW;
  HAL_GPIO_Init(GPIOG, &GPIO_InitStruct);

  /*Configure GPIO pin : XPT_IRQ_Pin */
  GPIO_InitStruct.Pin = XPT_IRQ_Pin;
  GPIO_InitStruct.Mode = GPIO_MODE_IT_RISING;
  GPIO_InitStruct.Pull = GPIO_NOPULL;
  HAL_GPIO_Init(XPT_IRQ_GPIO_Port, &GPIO_InitStruct);

/* USER CODE BEGIN MX_GPIO_Init_2 */
  HAL_GPIO_WritePin(FP_MATCH_LED_GPIO_Port, FP_MATCH_LED_Pin, GPIO_PIN_RESET);

  GPIO_InitStruct.Pin = FP_MATCH_LED_Pin;
  GPIO_InitStruct.Mode = GPIO_MODE_OUTPUT_PP;
  GPIO_InitStruct.Pull = GPIO_NOPULL;
  GPIO_InitStruct.Speed = GPIO_SPEED_FREQ_LOW;
  HAL_GPIO_Init(FP_MATCH_LED_GPIO_Port, &GPIO_InitStruct);
/* USER CODE END MX_GPIO_Init_2 */
}

/* USER CODE BEGIN 4 */

void HAL_TIM_PeriodElapsedCallback(TIM_HandleTypeDef *htim)
{
    if (htim->Instance == TIM14)
    {
        HAL_GPIO_TogglePin(LD_GPIO_Port, LD_Pin); /* heartbeat indicator */
    }
}

void HAL_UARTEx_RxEventCallback(UART_HandleTypeDef *huart, uint16_t Size)
{
    DebugLink_RxEventCallback(huart, Size);
}
/* USER CODE END 4 */

void Error_Handler(void)
{
  __disable_irq();
  while (1)
  {
  }
}
